VERSION ""

NS_ :

BS_:

BU_: SteeringWheel Display

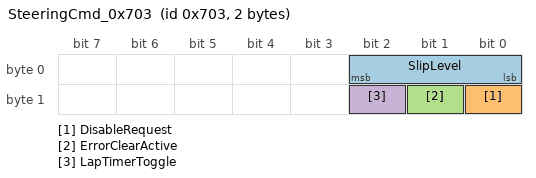
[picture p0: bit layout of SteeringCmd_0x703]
BO_ 1795 SteeringCmd_0x703: 2 SteeringWheel
 SG_ SlipLevel : 0|3@1+ (1,0) [0|7] ""  Display
 SG_ DisableRequest : 8|1@1+ (1,0) [0|1] ""  Display
 SG_ ErrorClearActive : 9|1@1+ (1,0) [0|1] ""  Display
 SG_ LapTimerToggle : 10|1@1+ (1,0) [0|1] ""  Display

BO_ 784 DriveMode_Request: 8 SteeringWheel
 SG_ DriveModeCode : 0|8@1+ (1,0) [0|255] ""  Display

CM_ BO_ 1795 "Steering command, standard CAN ID 0x703, DLC=2. SteeringWheel builds the whole frame on its private bus to Display; Display relays it verbatim to CANB (same ID, DLC and payload), also during the timing mode lock. Sent on events only: slip change, KEY1 release, KEY2 release, and every 20 ms while the exit-enable chord is active. Bits not defined here are 0. Reserved for a later merge: Byte2 DriveModeCode (0xFF = no mode request); not sent yet, DLC stays 2.";
CM_ SG_ 1795 LapTimerToggle "KEY1 (PB12) released alone: 1 in that single frame. Display starts/stops the lap or sprint timer on the rising edge; frames 1 within 300 ms count as one press. ECU ignores it. Not sent when KEY1 was part of a two-key press.";
CM_ SG_ 1795 ErrorClearActive "KEY2 (PB13) released alone: 1 in that single frame, then 0 in later frames. Display clears all alerts on the rising edge. Not sent when KEY2 was part of a two-key press.";
CM_ SG_ 1795 DisableRequest "Exit-enable request to ECU. 1 = request leaving the enabled (ready-to-drive) state. Set by the chord: hold KEY2 (PB13), then press KEY1 (PB12), keep both held for 300 ms. SteeringWheel then sends 1 every 20 ms while both keys stay held (at least 3 frames), and one frame with 0 after release. Replaces the former RecorderToggle meaning of this bit; Display firmware before this change set this bit on every lap-timer press. Recommended ECU handling (ECU confirmation pending): act after 2 consecutive frames with 1.";
CM_ SG_ 1795 SlipLevel "PA1 potentiometer quantized to eight levels 0..7; carried in every 0x703 frame.";
CM_ BO_ 784 "Rotary-switch drive mode, standard CAN ID 0x310, DLC=8, sent when the debounced position changes; Byte1..7 are 0. Display relays it to CANB unless the timing mode lock is active, and drops 0xFF. Vehicle definition: vehicle-interfaces Vehicle_CanB.dbc BO_ 784.";
CM_ SG_ 784 DriveModeCode "S1..S4 = ASCII '0'..'3' (48..51); 255 = no or several positions grounded (invalid).";

VAL_ 784 DriveModeCode 48 "AC" 49 "AX" 50 "Skidpad" 51 "EN" 255 "Invalid" ;
